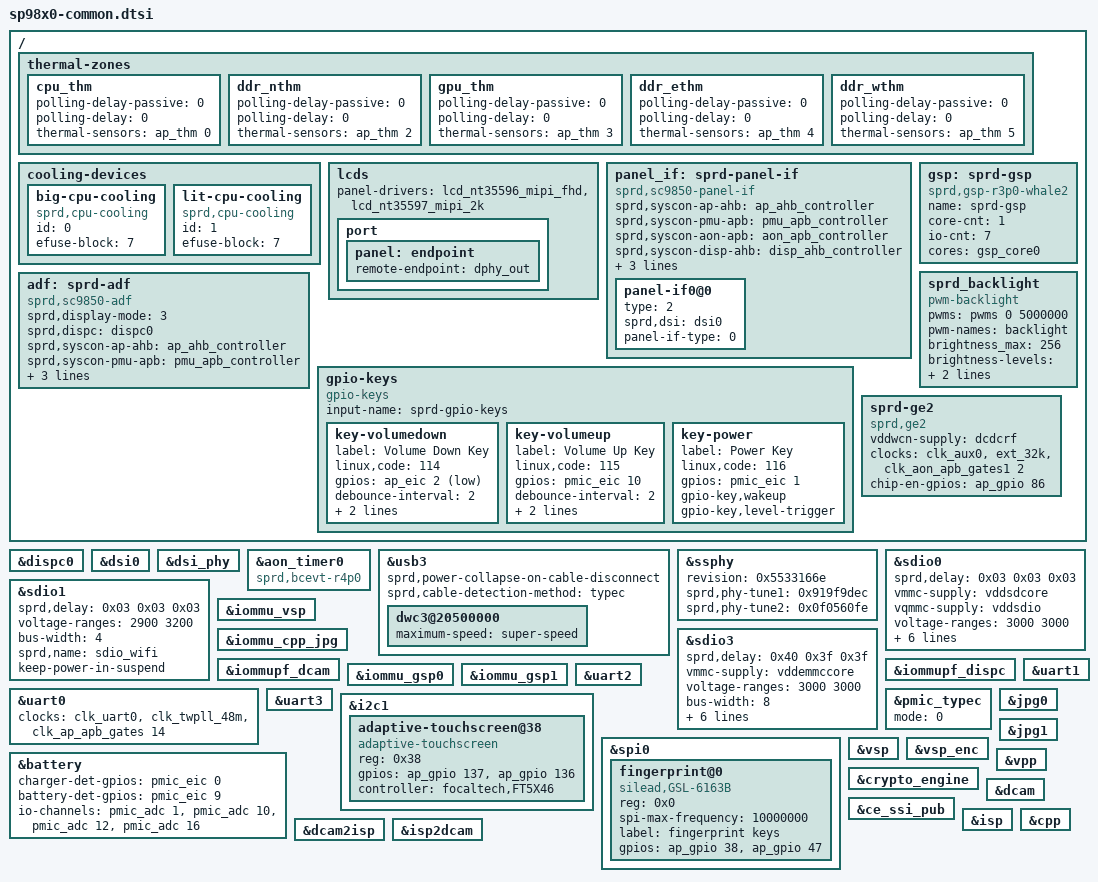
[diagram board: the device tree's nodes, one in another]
/*
 * Spreadtrum SP98x0 board common DTS file
 *
 * Copyright (C) 2016, Spreadtrum Communications Inc.
 *
 * This file is licensed under a dual GPLv2 or X11 license.
 */

#include "lcd_nt35596_mipi_fhd.dtsi"
#include "lcd_nt35597_mipi_2k.dtsi"

/ {
	thermal-zones {

		cpu_thm: cpu_thm {
			polling-delay-passive = <0>;
			polling-delay = <0>;
			thermal-sensors = <&ap_thm  0>;
		};

		ddr_nthm: ddr_nthm {
			polling-delay-passive = <0>;
			polling-delay = <0>;
			thermal-sensors = <&ap_thm  2>;
		};

		gpu_thm: gpu_thm {
			polling-delay-passive = <0>;
			polling-delay = <0>;
			thermal-sensors = <&ap_thm  3>;
		};

		ddr_ethm: ddr_ethm {
			polling-delay-passive = <0>;
			polling-delay = <0>;
			thermal-sensors = <&ap_thm  4>;
		};

		ddr_wthm: ddr_wthm {
			polling-delay-passive = <0>;
			polling-delay = <0>;
			thermal-sensors = <&ap_thm  5>;
		};
	};

	cooling-devices {
		big-cpu-cooling {
			compatible = "sprd,cpu-cooling";
			id = <0>;
			efuse-block = <7>;
		};
		lit-cpu-cooling {
			compatible = "sprd,cpu-cooling";
			id = <1>;
			efuse-block = <7>;
		};
	};

	lcds {
		panel-drivers = <
			&lcd_nt35596_mipi_fhd
			&lcd_nt35597_mipi_2k
		>;
		port {
			panel: endpoint {
				remote-endpoint = <&dphy_out>;
			};
		};
	};

	panel_if: sprd-panel-if {
		compatible = "sprd,sc9850-panel-if";
		sprd,syscon-ap-ahb = <&ap_ahb_controller>;
		sprd,syscon-pmu-apb = <&pmu_apb_controller>;
		sprd,syscon-aon-apb = <&aon_apb_controller>;
		sprd,syscon-disp-ahb = <&disp_ahb_controller>;
		sprd,syscon-ap-apb = <&ap_apb_controller>;

		pinctrl-0 = <&lcm_rstn_label>;
		pinctrl-names = "lcm_rstn";

		#address-cells = <1>;
		#size-cells = <0>;
		intf-nums = <1>;
		panel-if0@0 {
			type = <2>;
			sprd,dsi = <&dsi0>;
			panel-if-type = <0>;
		};
	};

	adf: sprd-adf {
		compatible = "sprd,sc9850-adf";
		status = "okay";
		sprd,display-mode = <3>;
		sprd,dispc = <&dispc0>;
		sprd,syscon-ap-ahb = <&ap_ahb_controller>;
		sprd,syscon-pmu-apb = <&pmu_apb_controller>;
		sprd,syscon-aon-apb = <&aon_apb_controller>;
		sprd,syscon-disp-ahb = <&disp_ahb_controller>;
		sprd,syscon-ap-apb = <&ap_apb_controller>;
	};

	gsp: sprd-gsp {
		 compatible = "sprd,gsp-r3p0-whale2";
		 name = "sprd-gsp";
		 core-cnt = <1>;
		 io-cnt = <7>;
		 cores = <&gsp_core0>;
	};

	sprd_backlight {
		compatible = "pwm-backlight";
		pwms = <&pwms 0 5000000>;
		pwm-names = "backlight";
		brightness_max = <256>;
		brightness-levels=<
			 10  10  10  10  10  10  10  10  10  10
			 10  11  12  13  14  15  16  17  18  19
			 20  21  22  23  24  25  26  27  28  29
			 30  31  32  33  34  35  36  37  38  39
			 40  41  42  43  44  45  46  47  48  49
			 50  51  52  53  54  55  56  57  58  59
			 60  61  62  63  64  65  66  67  68  69
			 70  71  72  73  74  75  76  77  78  79
			 80  81  82  83  84  85  86  87  88  89
			 90  91  92  93  94  95  96  97  98  99
			100 101 102 103 104 105 106 107 108 109
			110 111 112 113 114 115 116 117 118 119
			120 121 122 123 124 125 126 127 128 129
			130 131 132 133 134 135 136 137 138 139
			140 141 142 143 144 145 146 147 148 149
			150 151 152 153 154 155 156 157 158 159
			160 161 162 163 164 165 166 167 168 169
			170 171 172 173 174 175 176 177 178 179
			180 181 182 183 184 185 186 187 188 189
			190 191 192 193 194 195 196 197 198 199
			200 201 202 203 204 205 206 207 208 209
			210 211 212 213 214 215 216 217 218 219
			220 221 222 223 224 225 226 227 228 229
			230 231 232 233 234 235 236 237 238 239
			240 241 242 243 244 245 246 247 248 249
			250 251 252 253 254 255
			>;
		default-brightness-level = <127>;
	};

	gpio-keys {
		compatible = "gpio-keys";
		input-name = "sprd-gpio-keys";
		status = "okay";

		key-volumedown {
			label = "Volume Down Key";
			linux,code = <114>;
			gpios = <&ap_eic 2 1>;
			debounce-interval = <2>;
			gpio-key,wakeup;
			gpio-key,level-trigger;
		};

		key-volumeup {
			label = "Volume Up Key";
			linux,code = <115>;
			gpios = <&pmic_eic 10 0>;
			debounce-interval = <2>;
			gpio-key,wakeup;
			gpio-key,level-trigger;
		};

		key-power {
			label = "Power Key";
			linux,code = <116>;
			gpios = <&pmic_eic 1 0>;
			gpio-key,wakeup;
			gpio-key,level-trigger;
		};
	};

	sprd-ge2 {
		compatible = "sprd,ge2";
		vddwcn-supply = <&dcdcrf>;
		clock-names = "clk_32k","source","enable";
		clocks = <&clk_aux0>,<&ext_32k>,
			 <&clk_aon_apb_gates1 2>;
		chip-en-gpios = <&ap_gpio 86 0>;
	};
};

&dispc0 {
	status = "okay";
};

&dsi0 {
	status = "okay";
};

&dsi_phy {
	status = "okay";
};

&aon_timer0 {
	status = "okay";
	compatible = "sprd,bcevt-r4p0";
};

&usb3 {
	status = "okay";
	sprd,power-collapse-on-cable-disconnect;
	sprd,cable-detection-method = "typec"; /* typec or gpios or none */
	dwc3@20500000 {
		maximum-speed = "super-speed"; /* super-speed, high-speed, full-speed and etc. */
	};
};

&ssphy {
	status = "okay";
	revision = <0x5533166e>; /* 0x5533286e - USB3_PHY_TSMC_28nm; 0x5533166e - USB3_PHY_TMSC_16nm */
	sprd,phy-tune1 = <0x919f9dec>;
	sprd,phy-tune2 = <0x0f0560fe>;
};

&sdio0 {
	sprd,delay = <0x03 0x03 0x03>;
	vmmc-supply = <&vddsdcore>;
	vqmmc-supply = <&vddsdio>;
	voltage-ranges = <3000 3000>;
	bus-width = <4>;
	non-removable;
	sd-uhs-sdr104;
	sd-uhs-sdr50;
	sprd,name = "sdio_sd";
	pinctrl-0 = <&vio_sd0_ms>;
	pinctrl-names = "pinctrl_reg0";
	status = "okay";
};

&sdio1 {
	sprd,delay = <0x03 0x03 0x03>;
	voltage-ranges = <2900 3200>;
	bus-width = <4>;
	sprd,name = "sdio_wifi";
	keep-power-in-suspend;
	status = "okay";
};

&sdio3 {
	sprd,delay = <0x40 0x3f 0x3f>;
	vmmc-supply = <&vddemmccore>;
	voltage-ranges = <3000 3000>;
	bus-width = <8>;
	non-removable;
	cap-mmc-hw-reset;
	mmc-hs200-1_8v;
	mmc-ddr-1_8v;
	mmc-hs400-1_8v;
	sprd,name = "sdio_emmc";
	status = "okay";
};

&iommu_vsp {
	status = "okay";
};

&iommu_cpp_jpg {
	status = "okay";
};

&iommupf_dcam {
	status = "okay";
};

&iommupf_dispc {
	status = "okay";
};

&iommu_gsp0 {
	status = "okay";
};

&iommu_gsp1{
	status = "okay";
};

&uart0 {
	status = "okay";
	clocks = <&clk_uart0>, <&clk_twpll_48m>,
		 <&clk_ap_apb_gates 14>;
};

&uart1 {
	status = "okay";
};

&uart2 {
	status = "okay";
};

&uart3 {
	status = "okay";
};

&i2c1 {
	status = "okay";

	adaptive-touchscreen@38 {
		compatible = "adaptive-touchscreen";
		reg = <0x38>;
		gpios = <&ap_gpio 137 0
			&ap_gpio 136 0>;
		controller = "focaltech,FT5X46";
		};
};

&spi0 {
	status = "okay";

	fingerprint@0 {
		compatible = "silead,GSL-6163B";
		reg = <0x0>;
		spi-max-frequency = <10000000>;
		label = "fingerprint keys";
		gpios = <&ap_gpio 38 0
			&ap_gpio 47 0 >;
	};
};

&battery {
	charger-det-gpios = <&pmic_eic 0 0>;
	battery-det-gpios = <&pmic_eic 9 0>;
	io-channels = <&pmic_adc 1>,<&pmic_adc 10>,
			<&pmic_adc 12>,<&pmic_adc 16>;
	io-channel-names = "adc_temp","adc_vbat",
			"adc_vchg","adc_isense";
	status = "okay";
};

&pmic_typec {
	status = "okay";
	mode = <0>;
};

&jpg0 {
	status = "okay";
};

&jpg1 {
	status = "okay";
};

&vsp {
	status = "okay";
};

&vsp_enc {
	status = "okay";
};

&vpp {
	status = "okay";
};

&crypto_engine {
	status = "okay";
};

&ce_ssi_pub {
	status = "okay";
};

&dcam {
	status = "okay";
};

&isp {
	status = "okay";
};

&cpp {
	status = "okay";
};

&dcam2isp {
	status = "okay";
};

&isp2dcam {
	status = "okay";
};
